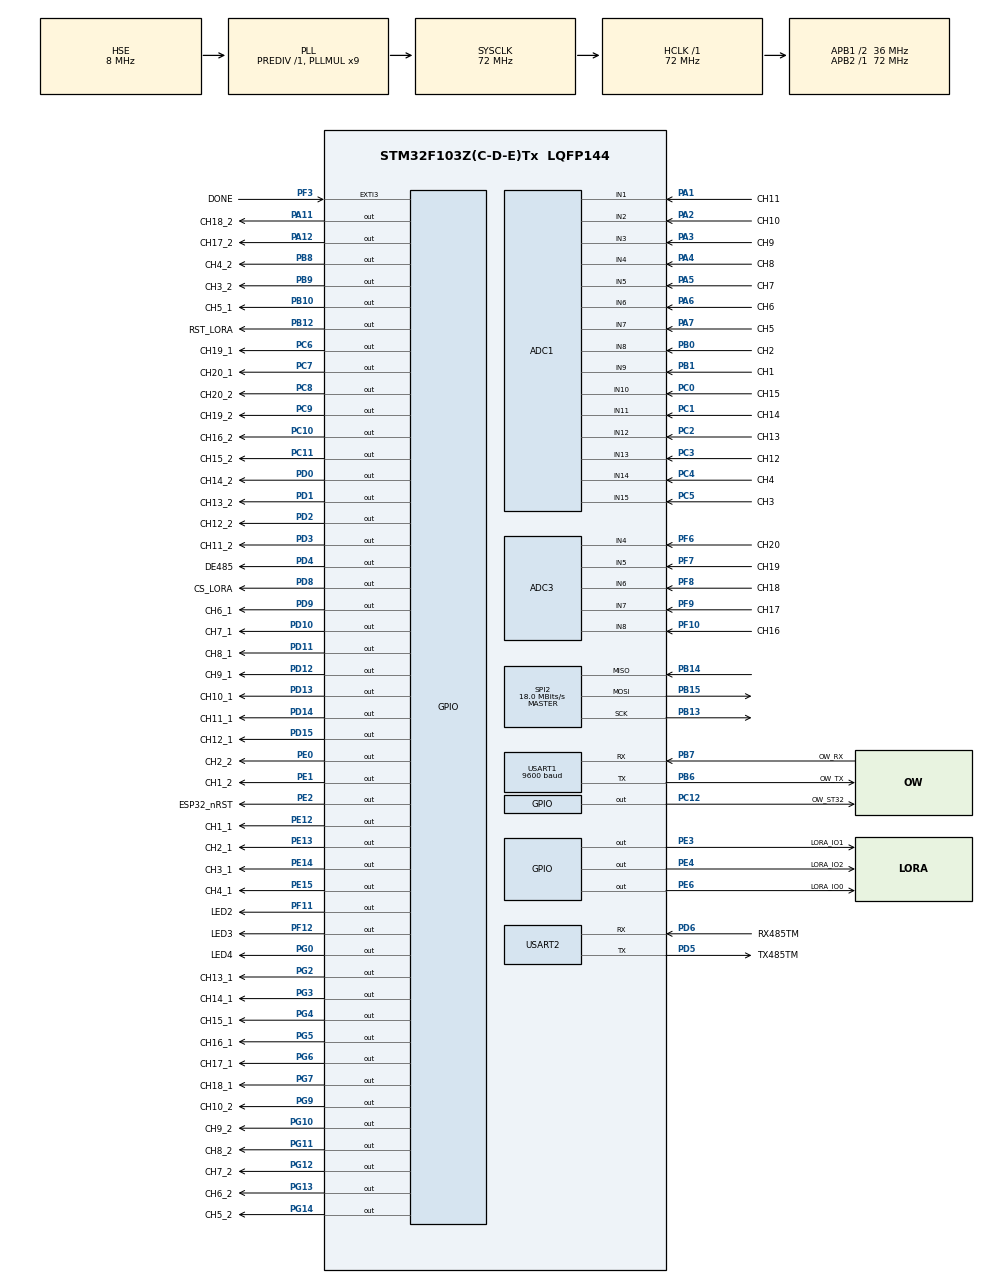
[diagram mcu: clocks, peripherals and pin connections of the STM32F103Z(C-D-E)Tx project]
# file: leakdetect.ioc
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ADC1.Channel-1\#ChannelRegularConversion=ADC_CHANNEL_9
ADC1.NbrOfConversionFlag=1
ADC1.Rank-1\#ChannelRegularConversion=1
ADC1.SamplingTime-1\#ChannelRegularConversion=ADC_SAMPLETIME_1CYCLE_5
ADC1.master=1
ADC3.Channel-1\#ChannelRegularConversion=ADC_CHANNEL_8
ADC3.NbrOfConversionFlag=1
ADC3.Rank-1\#ChannelRegularConversion=1
ADC3.SamplingTime-1\#ChannelRegularConversion=ADC_SAMPLETIME_1CYCLE_5
Dma.Request0=SPI2_RX
Dma.Request1=SPI2_TX
Dma.Request2=USART2_RX
Dma.Request3=USART2_TX
Dma.SPI2_RX.0.Direction=DMA_PERIPH_TO_MEMORY
Dma.SPI2_RX.0.Instance=DMA1_Channel4
Dma.SPI2_RX.0.MemDataAlignment=DMA_MDATAALIGN_BYTE
Dma.SPI2_RX.0.MemInc=DMA_MINC_ENABLE
Dma.SPI2_RX.0.Mode=DMA_NORMAL
Dma.SPI2_RX.0.PeriphDataAlignment=DMA_PDATAALIGN_BYTE
Dma.SPI2_RX.0.PeriphInc=DMA_PINC_DISABLE
Dma.SPI2_RX.0.Priority=DMA_PRIORITY_LOW
Dma.SPI2_TX.1.Direction=DMA_MEMORY_TO_PERIPH
Dma.SPI2_TX.1.Instance=DMA1_Channel5
Dma.SPI2_TX.1.MemDataAlignment=DMA_MDATAALIGN_BYTE
Dma.SPI2_TX.1.MemInc=DMA_MINC_ENABLE
Dma.SPI2_TX.1.Mode=DMA_NORMAL
Dma.SPI2_TX.1.PeriphDataAlignment=DMA_PDATAALIGN_BYTE
Dma.SPI2_TX.1.PeriphInc=DMA_PINC_DISABLE
Dma.SPI2_TX.1.Priority=DMA_PRIORITY_LOW
Dma.USART2_RX.2.Direction=DMA_PERIPH_TO_MEMORY
Dma.USART2_RX.2.Instance=DMA1_Channel6
Dma.USART2_RX.2.MemDataAlignment=DMA_MDATAALIGN_BYTE
Dma.USART2_RX.2.MemInc=DMA_MINC_ENABLE
Dma.USART2_RX.2.Mode=DMA_NORMAL
Dma.USART2_RX.2.PeriphDataAlignment=DMA_PDATAALIGN_BYTE
Dma.USART2_RX.2.PeriphInc=DMA_PINC_DISABLE
Dma.USART2_RX.2.Priority=DMA_PRIORITY_LOW
Dma.USART2_TX.3.Direction=DMA_MEMORY_TO_PERIPH
Dma.USART2_TX.3.Instance=DMA1_Channel7
Dma.USART2_TX.3.MemDataAlignment=DMA_MDATAALIGN_BYTE
Dma.USART2_TX.3.MemInc=DMA_MINC_ENABLE
Dma.USART2_TX.3.Mode=DMA_NORMAL
Dma.USART2_TX.3.PeriphDataAlignment=DMA_PDATAALIGN_BYTE
Dma.USART2_TX.3.PeriphInc=DMA_PINC_DISABLE
Dma.USART2_TX.3.Priority=DMA_PRIORITY_LOW
FREERTOS.Tasks01=defaultTask,0,128,StartDefaultTask,Default,NULL,Dynamic,NULL,NULL;modbusTask,0,128,StartTaskModBus,Default,NULL,Static,modbusTaskBuffer,modbusTaskControlBlock;leakMeterTask,0,128,StartTaskLeakMeter,Default,NULL,Static,leakMeterTaskBuffer,leakMeterTaskControlBlock;oneWireTask,-3,128,StartTaskOneWire,Default,NULL,Static,oneWireTaskBuffer,oneWireTaskControlBlock
FREERTOS.configCHECK_FOR_STACK_OVERFLOW=2
FREERTOS.configGENERATE_RUN_TIME_STATS=1
FREERTOS.configRECORD_STACK_HIGH_ADDRESS=1
FREERTOS.configUSE_MALLOC_FAILED_HOOK=1
FREERTOS.configUSE_NEWLIB_REENTRANT=1
FREERTOS.configUSE_STATS_FORMATTING_FUNCTIONS=1
FREERTOS.configUSE_TICKLESS_IDLE=1
Mcu.Family=STM32F1
Mcu.Name=STM32F103Z(C-D-E)Tx
Mcu.Package=LQFP144
NVIC.ADC1_2_IRQn=true\:5\:0\:false\:false\:true\:true\:true\:true\:true
NVIC.ADC3_IRQn=true\:5\:0\:false\:false\:true\:true\:true\:true\:true
NVIC.DMA1_Channel4_IRQn=true\:5\:0\:false\:false\:true\:true\:false\:true\:true
NVIC.DMA1_Channel5_IRQn=true\:5\:0\:false\:false\:true\:true\:false\:true\:true
NVIC.DMA1_Channel6_IRQn=true\:5\:0\:false\:false\:true\:true\:false\:true\:true
NVIC.DMA1_Channel7_IRQn=true\:5\:0\:false\:false\:true\:true\:false\:true\:true
NVIC.PriorityGroup=NVIC_PRIORITYGROUP_4
NVIC.RTC_IRQn=true\:5\:0\:false\:false\:true\:true\:true\:true\:true
NVIC.SPI2_IRQn=true\:5\:0\:false\:false\:true\:true\:true\:true\:true
NVIC.TIM8_UP_IRQn=true\:15\:0\:false\:false\:true\:false\:false\:true\:true
NVIC.TimeBase=TIM8_UP_IRQn
NVIC.TimeBaseIP=TIM8
NVIC.USART1_IRQn=true\:5\:0\:false\:false\:true\:true\:true\:true\:true
NVIC.USART2_IRQn=true\:5\:0\:false\:false\:true\:true\:true\:true\:true
OSC_IN.GPIO_Label=OSC_IN
OSC_IN.Mode=HSE-External-Oscillator
OSC_IN.Signal=RCC_OSC_IN
OSC_OUT.GPIO_Label=OSC_OUT
OSC_OUT.Mode=HSE-External-Oscillator
OSC_OUT.Signal=RCC_OSC_OUT
PA0-WKUP.Mode=SYS_WakeUp0
PA0-WKUP.Signal=SYS_WKUP
PA1.GPIO_Label=CH11
PA1.Signal=ADCx_IN1
PA11.GPIO_Label=CH18_2
PA11.Signal=GPIO_Output
PA12.GPIO_Label=CH17_2
PA12.Signal=GPIO_Output
PA13.GPIO_Label=JTMS_SWDIO
PA13.Mode=Serial_Wire
PA13.Signal=SYS_JTMS-SWDIO
PA14.GPIO_Label=JTCK_SWCLK
PA14.Mode=Serial_Wire
PA14.Signal=SYS_JTCK-SWCLK
PA15.GPIO_Label=JTDI
PA15.Signal=SYS_JTDI
PA2.GPIO_Label=CH10
PA2.Signal=ADCx_IN2
PA3.GPIO_Label=CH9
PA3.Signal=ADCx_IN3
PA4.GPIO_Label=CH8
PA4.Signal=ADCx_IN4
PA5.GPIO_Label=CH7
PA5.Signal=ADCx_IN5
PA6.GPIO_Label=CH6
PA6.Signal=ADCx_IN6
PA7.GPIO_Label=CH5
PA7.Signal=ADCx_IN7
PB0.GPIO_Label=CH2
PB0.Signal=ADCx_IN8
PB1.GPIO_Label=CH1
PB1.Signal=ADCx_IN9
PB10.GPIO_Label=CH5_1
PB10.Signal=GPIO_Output
PB12.GPIO_Label=RST_LORA
PB12.Signal=GPIO_Output
PB13.Mode=Full_Duplex_Master
PB13.Signal=SPI2_SCK
PB14.Mode=Full_Duplex_Master
PB14.Signal=SPI2_MISO
PB15.Mode=Full_Duplex_Master
PB15.Signal=SPI2_MOSI
PB4.GPIO_Label=JTRST
PB4.Signal=SYS_NJTRST
PB6.GPIO_Label=OW_TX
PB6.Mode=Asynchronous
PB6.Signal=USART1_TX
PB7.GPIO_Label=OW_RX
PB7.GPIO_PuPd=GPIO_PULLUP
PB7.Mode=Asynchronous
PB7.Signal=USART1_RX
PB8.GPIO_Label=CH4_2
PB8.Signal=GPIO_Output
PB9.GPIO_Label=CH3_2
PB9.Signal=GPIO_Output
PC0.GPIO_Label=CH15
PC0.Signal=ADCx_IN10
PC1.GPIO_Label=CH14
PC1.Signal=ADCx_IN11
PC10.GPIO_Label=CH16_2
PC10.Signal=GPIO_Output
PC11.GPIO_Label=CH15_2
PC11.Signal=GPIO_Output
PC12.GPIO_Label=OW_ST32
PC12.Signal=GPIO_Output
PC14-OSC32_IN.Mode=LSE-External-Oscillator
PC14-OSC32_IN.Signal=RCC_OSC32_IN
PC15-OSC32_OUT.Mode=LSE-External-Oscillator
PC15-OSC32_OUT.Signal=RCC_OSC32_OUT
PC2.GPIO_Label=CH13
PC2.Signal=ADCx_IN12
PC3.GPIO_Label=CH12
PC3.Signal=ADCx_IN13
PC4.GPIO_Label=CH4
PC4.Signal=ADCx_IN14
PC5.GPIO_Label=CH3
PC5.Signal=ADCx_IN15
PC6.GPIO_Label=CH19_1
PC6.Signal=GPIO_Output
PC7.GPIO_Label=CH20_1
PC7.Signal=GPIO_Output
PC8.GPIO_Label=CH20_2
PC8.Signal=GPIO_Output
PC9.GPIO_Label=CH19_2
PC9.Signal=GPIO_Output
PD0.GPIO_Label=CH14_2
PD0.Signal=GPIO_Output
PD1.GPIO_Label=CH13_2
PD1.Signal=GPIO_Output
PD10.GPIO_Label=CH7_1
PD10.Signal=GPIO_Output
PD11.GPIO_Label=CH8_1
PD11.Signal=GPIO_Output
PD12.GPIO_Label=CH9_1
PD12.Signal=GPIO_Output
PD13.GPIO_Label=CH10_1
PD13.Signal=GPIO_Output
PD14.GPIO_Label=CH11_1
PD14.Signal=GPIO_Output
PD15.GPIO_Label=CH12_1
PD15.Signal=GPIO_Output
PD2.GPIO_Label=CH12_2
PD2.Signal=GPIO_Output
PD3.GPIO_Label=CH11_2
PD3.Signal=GPIO_Output
PD4.GPIO_Label=DE485
PD4.Signal=GPIO_Output
PD5.GPIO_Label=TX485TM
PD5.Mode=Asynchronous
PD5.Signal=USART2_TX
PD6.GPIO_Label=RX485TM
PD6.GPIO_PuPd=GPIO_PULLUP
PD6.Mode=Asynchronous
PD6.Signal=USART2_RX
PD8.GPIO_Label=CS_LORA
PD8.Signal=GPIO_Output
PD9.GPIO_Label=CH6_1
PD9.Signal=GPIO_Output
PE0.GPIO_Label=CH2_2
PE0.Signal=GPIO_Output
PE1.GPIO_Label=CH1_2
PE1.Signal=GPIO_Output
PE12.GPIO_Label=CH1_1
PE12.Signal=GPIO_Output
PE13.GPIO_Label=CH2_1
PE13.Signal=GPIO_Output
PE14.GPIO_Label=CH3_1
PE14.Signal=GPIO_Output
PE15.GPIO_Label=CH4_1
PE15.Signal=GPIO_Output
PE2.GPIO_Label=ESP32_nRST
PE2.Signal=GPIO_Output
PE3.GPIO_Label=LORA_IO1
PE3.Signal=GPIO_Output
PE4.GPIO_Label=LORA_IO2
PE4.Signal=GPIO_Output
PE6.GPIO_Label=LORA_IO0
PE6.Signal=GPIO_Output
PF10.GPIO_Label=CH16
PF10.Mode=IN8
PF10.Signal=ADC3_IN8
PF11.GPIO_Label=LED2
PF11.Signal=GPIO_Output
PF12.GPIO_Label=LED3
PF12.Signal=GPIO_Output
PF3.GPIO_Label=DONE
PF3.Signal=GPXTI3
PF6.GPIO_Label=CH20
PF6.Mode=IN4
PF6.Signal=ADC3_IN4
PF7.GPIO_Label=CH19
PF7.Mode=IN5
PF7.Signal=ADC3_IN5
PF8.GPIO_Label=CH18
PF8.Mode=IN6
PF8.Signal=ADC3_IN6
PF9.GPIO_Label=CH17
PF9.Mode=IN7
PF9.Signal=ADC3_IN7
PG0.GPIO_Label=LED4
PG0.Signal=GPIO_Output
PG10.GPIO_Label=CH9_2
PG10.Signal=GPIO_Output
PG11.GPIO_Label=CH8_2
PG11.Signal=GPIO_Output
PG12.GPIO_Label=CH7_2
PG12.Signal=GPIO_Output
PG13.GPIO_Label=CH6_2
PG13.Signal=GPIO_Output
PG14.GPIO_Label=CH5_2
PG14.Signal=GPIO_Output
PG2.GPIO_Label=CH13_1
PG2.Signal=GPIO_Output
PG3.GPIO_Label=CH14_1
PG3.Signal=GPIO_Output
PG4.GPIO_Label=CH15_1
PG4.Signal=GPIO_Output
PG5.GPIO_Label=CH16_1
PG5.Signal=GPIO_Output
PG6.GPIO_Label=CH17_1
PG6.Signal=GPIO_Output
PG7.GPIO_Label=CH18_1
PG7.Signal=GPIO_Output
PG9.GPIO_Label=CH10_2
PG9.Signal=GPIO_Output
ProjectManager.HeapSize=0x200
ProjectManager.StackSize=0x400
ProjectManager.TargetToolchain=STM32CubeIDE
RCC.ADCPresc=RCC_ADCPCLK2_DIV6
RCC.AHBFreq_Value=72000000
RCC.APB1CLKDivider=RCC_HCLK_DIV2
RCC.APB1Freq_Value=36000000
RCC.APB1TimFreq_Value=72000000
RCC.APB2Freq_Value=72000000
RCC.APB2TimFreq_Value=72000000
RCC.HCLKFreq_Value=72000000
RCC.PLLMUL=RCC_PLL_MUL9
RCC.PLLSourceVirtual=RCC_PLLSOURCE_HSE
RCC.RTCClockSelection=RCC_RTCCLKSOURCE_LSE
RCC.SYSCLKFreq_VALUE=72000000
RCC.SYSCLKSource=RCC_SYSCLKSOURCE_PLLCLK
RCC.USBFreq_Value=72000000
SH.ADCx_IN1.0=ADC1_IN1,IN1
SH.ADCx_IN10.0=ADC1_IN10,IN10
SH.ADCx_IN11.0=ADC1_IN11,IN11
SH.ADCx_IN12.0=ADC1_IN12,IN12
SH.ADCx_IN13.0=ADC1_IN13,IN13
SH.ADCx_IN14.0=ADC1_IN14,IN14
SH.ADCx_IN15.0=ADC1_IN15,IN15
SH.ADCx_IN2.0=ADC1_IN2,IN2
SH.ADCx_IN3.0=ADC1_IN3,IN3
SH.ADCx_IN4.0=ADC1_IN4,IN4
SH.ADCx_IN5.0=ADC1_IN5,IN5
SH.ADCx_IN6.0=ADC1_IN6,IN6
SH.ADCx_IN7.0=ADC1_IN7,IN7
SH.ADCx_IN8.0=ADC1_IN8,IN8
SH.ADCx_IN9.0=ADC1_IN9,IN9
SPI2.BaudRatePrescaler=SPI_BAUDRATEPRESCALER_2
SPI2.CalculateBaudRate=18.0 MBits/s
SPI2.Direction=SPI_DIRECTION_2LINES
SPI2.Mode=SPI_MODE_MASTER
SPI2.VirtualType=VM_MASTER
USART1.BaudRate=9600
USART1.VirtualMode=VM_ASYNC
USART2.VirtualMode=VM_ASYNC
VP_CRC_VS_CRC.Mode=CRC_Activate
VP_FREERTOS_VS_CMSIS_V1.Mode=CMSIS_V1
VP_IWDG_VS_IWDG.Mode=IWDG_Activate
VP_RTC_VS_RTC_Activate.Mode=RTC_Enabled
VP_RTC_VS_RTC_Calendar.Mode=RTC_Calendar
VP_SYS_VS_tim8.Mode=TIM8
board=custom

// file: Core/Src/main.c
/* USER CODE BEGIN Header */
/**
  ******************************************************************************
  * @file           : main.c
  * @brief          : Main program body
  ******************************************************************************
  * @attention
  *
  * Copyright (c) 2024 STMicroelectronics.
  * All rights reserved.
  *
  * This software is licensed under terms that can be found in the LICENSE file
  * in the root directory of this software component.
  * If no LICENSE file comes with this software, it is provided AS-IS.
  *
  ******************************************************************************
  */
/* USER CODE END Header */
#include "main.h"
#include "cmsis_os.h"

/* USER CODE BEGIN Includes */
#include <stdio.h>
#include <string.h>
#include <math.h>
/* USER CODE END Includes */

/* USER CODE BEGIN PD */
#define VREF        3.3   // Опорное напряжение АЦП
#define ADC_MAX     4095   // Максимальное значение для 12-битного АЦП
#define R1          10000  // Значение известного сопротивления R1 в омах
#define UART_BUFFER_SIZE 256
/* USER CODE END PD */

ADC_HandleTypeDef hadc1;
ADC_HandleTypeDef hadc3;

CRC_HandleTypeDef hcrc;

IWDG_HandleTypeDef hiwdg;

RTC_HandleTypeDef hrtc;

SPI_HandleTypeDef hspi2;
DMA_HandleTypeDef hdma_spi2_rx;
DMA_HandleTypeDef hdma_spi2_tx;

UART_HandleTypeDef huart1;
UART_HandleTypeDef huart2;
DMA_HandleTypeDef hdma_usart2_rx;
DMA_HandleTypeDef hdma_usart2_tx;

osThreadId defaultTaskHandle;
osThreadId modbusTaskHandle;
uint32_t modbusTaskBuffer[ 128 ];
osStaticThreadDef_t modbusTaskControlBlock;
osThreadId leakMeterTaskHandle;
uint32_t leakMeterTaskBuffer[ 128 ];
osStaticThreadDef_t leakMeterTaskControlBlock;
osThreadId oneWireTaskHandle;
uint32_t oneWireTaskBuffer[ 128 ];
osStaticThreadDef_t oneWireTaskControlBlock;
/* USER CODE BEGIN PV */
typedef struct {
    GPIO_TypeDef* gpio_port1;  // Указатель на порт GPIO 1 канал
    uint16_t toggle_pin1;      // Первый пин для ToggleCurrentDirection
    GPIO_TypeDef* gpio_port2;  // Указатель на порт GPIO 2 канал
    uint16_t toggle_pin2;      // Второй пин для ToggleCurrentDirection
    uint32_t adc_channel;      // Канал АЦП, используемый для данной группы
    ADC_HandleTypeDef* hadc;   // Указатель на обработчик АЦП
    uint8_t channel_number;    // Номер канала
} ChannelConfig;

ChannelConfig channels[] = {

    {GPIOE, GPIO_PIN_12, GPIOE, GPIO_PIN_1, ADC_CHANNEL_9, &hadc1, 1}, // канал 1
    {GPIOE, GPIO_PIN_13, GPIOE, GPIO_PIN_0, ADC_CHANNEL_8, &hadc1, 2}, // канал 2
    {GPIOE, GPIO_PIN_14, GPIOB, GPIO_PIN_9, ADC_CHANNEL_15, &hadc1, 3}, // канал 3
    {GPIOE, GPIO_PIN_15, GPIOB, GPIO_PIN_8, ADC_CHANNEL_14, &hadc1, 4}, // канал 4
    {GPIOB, GPIO_PIN_10, GPIOG, GPIO_PIN_14, ADC_CHANNEL_7, &hadc1, 5}, // канал 5
    {GPIOD, GPIO_PIN_9, GPIOG, GPIO_PIN_13, ADC_CHANNEL_6, &hadc1, 6}, // канал 6
    {GPIOD, GPIO_PIN_10, GPIOG, GPIO_PIN_12, ADC_CHANNEL_5, &hadc1, 7}, // канал 7
    {GPIOD, GPIO_PIN_11, GPIOG, GPIO_PIN_11, ADC_CHANNEL_4, &hadc1, 8}, // канал 8
    {GPIOD, GPIO_PIN_12, GPIOG, GPIO_PIN_10, ADC_CHANNEL_3, &hadc1, 9}, // канал 9
    {GPIOD, GPIO_PIN_13, GPIOG, GPIO_PIN_9, ADC_CHANNEL_2, &hadc1, 10}, // канал 10
    {GPIOD, GPIO_PIN_14, GPIOD, GPIO_PIN_3, ADC_CHANNEL_1, &hadc1, 11}, // канал 11
    {GPIOD, GPIO_PIN_15, GPIOD, GPIO_PIN_2, ADC_CHANNEL_13, &hadc1, 12}, // канал 12
    {GPIOG, GPIO_PIN_2, GPIOD, GPIO_PIN_1, ADC_CHANNEL_12, &hadc1, 13}, // канал 13
    {GPIOG, GPIO_PIN_3, GPIOD, GPIO_PIN_0, ADC_CHANNEL_11, &hadc1, 14}, // канал 14
    {GPIOG, GPIO_PIN_4, GPIOC, GPIO_PIN_11, ADC_CHANNEL_10, &hadc1, 15}, // канал 15
    {GPIOG, GPIO_PIN_5, GPIOC, GPIO_PIN_10, ADC_CHANNEL_8, &hadc3, 16}, // канал 16
    {GPIOG, GPIO_PIN_6, GPIOA, GPIO_PIN_12, ADC_CHANNEL_7, &hadc3, 17}, // канал 17
    {GPIOG, GPIO_PIN_7, GPIOA, GPIO_PIN_11, ADC_CHANNEL_6, &hadc3, 18}, // канал 18
    {GPIOC, GPIO_PIN_6, GPIOC, GPIO_PIN_9, ADC_CHANNEL_5, &hadc3, 19}, // канал 19

    {GPIOC, GPIO_PIN_7, GPIOC, GPIO_PIN_8, ADC_CHANNEL_4, &hadc3, 20}, // канал 20
};

void ToggleCurrentDirection(GPIO_TypeDef* gpio_port1, uint16_t pin1, GPIO_TypeDef* gpio_port2, uint16_t pin2, uint16_t time_delay);
void ProcessChannel(ChannelConfig* channel);
void ConfigureUnusedChannels(ChannelConfig* active_channel);
void ResetChannelConfigs(void);
/* USER CODE END PV */

void SystemClock_Config(void);
static void MX_GPIO_Init(void);
static void MX_DMA_Init(void);
static void MX_ADC1_Init(void);
static void MX_ADC3_Init(void);
static void MX_USART1_UART_Init(void);
static void MX_RTC_Init(void);
static void MX_SPI2_Init(void);
static void MX_USART2_UART_Init(void);
static void MX_CRC_Init(void);
static void MX_IWDG_Init(void);
void StartDefaultTask(void const * argument);
void StartTaskModBus(void const * argument);
void StartTaskLeakMeter(void const * argument);
void StartTaskOneWire(void const * argument);

/* USER CODE BEGIN 0 */
int _write(int file, char *data, int len)
{
    // Отключите отладочный вывод через UART, чтобы избежать отправки лишних данных
    return len;
}
/* USER CODE END 0 */

int main(void)
{

  /* MCU Configuration--------------------------------------------------------*/

  /* Reset of all peripherals, Initializes the Flash interface and the Systick. */
  HAL_Init();

  /* Configure the system clock */
  SystemClock_Config();

  /* Initialize all configured peripherals */
  MX_GPIO_Init();
  MX_DMA_Init();
  MX_ADC1_Init();
  MX_ADC3_Init();
  MX_USART1_UART_Init();
  MX_RTC_Init();
  MX_SPI2_Init();
  MX_USART2_UART_Init();
  MX_CRC_Init();
  MX_IWDG_Init();

  /* Create the thread(s) */
  /* definition and creation of defaultTask */
  osThreadDef(defaultTask, StartDefaultTask, osPriorityNormal, 0, 128);
  defaultTaskHandle = osThreadCreate(osThread(defaultTask), NULL);

  /* definition and creation of modbusTask */
  osThreadStaticDef(modbusTask, StartTaskModBus, osPriorityNormal, 0, 128, modbusTaskBuffer, &modbusTaskControlBlock);
  modbusTaskHandle = osThreadCreate(osThread(modbusTask), NULL);

  /* definition and creation of leakMeterTask */
  osThreadStaticDef(leakMeterTask, StartTaskLeakMeter, osPriorityNormal, 0, 128, leakMeterTaskBuffer, &leakMeterTaskControlBlock);
  leakMeterTaskHandle = osThreadCreate(osThread(leakMeterTask), NULL);

  /* definition and creation of oneWireTask */
  osThreadStaticDef(oneWireTask, StartTaskOneWire, osPriorityIdle, 0, 128, oneWireTaskBuffer, &oneWireTaskControlBlock);
  oneWireTaskHandle = osThreadCreate(osThread(oneWireTask), NULL);

  /* Start scheduler */
  osKernelStart();

  /* We should never get here as control is now taken by the scheduler */

  /* Infinite loop */
  /* USER CODE BEGIN WHILE */
  while (1)
  {
    for (int i = 0; i < sizeof(channels)/sizeof(channels[0]); i++) {
         ProcessChannel(&channels[i]);
    }

    /* USER CODE END WHILE */

  }
}

void SystemClock_Config(void)
{
  RCC_OscInitTypeDef RCC_OscInitStruct = {0};
  RCC_ClkInitTypeDef RCC_ClkInitStruct = {0};
  RCC_PeriphCLKInitTypeDef PeriphClkInit = {0};

  /** Initializes the RCC Oscillators according to the specified parameters
  * in the RCC_OscInitTypeDef structure.
  */
  RCC_OscInitStruct.OscillatorType = RCC_OSCILLATORTYPE_LSI|RCC_OSCILLATORTYPE_HSE
                              |RCC_OSCILLATORTYPE_LSE;
  RCC_OscInitStruct.HSEState = RCC_HSE_ON;
  RCC_OscInitStruct.HSEPredivValue = RCC_HSE_PREDIV_DIV1;
  RCC_OscInitStruct.LSEState = RCC_LSE_ON;
  RCC_OscInitStruct.HSIState = RCC_HSI_ON;
  RCC_OscInitStruct.LSIState = RCC_LSI_ON;
  RCC_OscInitStruct.PLL.PLLState = RCC_PLL_ON;
  RCC_OscInitStruct.PLL.PLLSource = RCC_PLLSOURCE_HSE;
  RCC_OscInitStruct.PLL.PLLMUL = RCC_PLL_MUL9;
  if (HAL_RCC_OscConfig(&RCC_OscInitStruct) != HAL_OK)
  {
    Error_Handler();
  }

  /** Initializes the CPU, AHB and APB buses clocks
  */
  RCC_ClkInitStruct.ClockType = RCC_CLOCKTYPE_HCLK|RCC_CLOCKTYPE_SYSCLK
                              |RCC_CLOCKTYPE_PCLK1|RCC_CLOCKTYPE_PCLK2;
  RCC_ClkInitStruct.SYSCLKSource = RCC_SYSCLKSOURCE_PLLCLK;
  RCC_ClkInitStruct.AHBCLKDivider = RCC_SYSCLK_DIV1;
  RCC_ClkInitStruct.APB1CLKDivider = RCC_HCLK_DIV2;
  RCC_ClkInitStruct.APB2CLKDivider = RCC_HCLK_DIV1;

  if (HAL_RCC_ClockConfig(&RCC_ClkInitStruct, FLASH_LATENCY_2) != HAL_OK)
  {
    Error_Handler();
  }
  PeriphClkInit.PeriphClockSelection = RCC_PERIPHCLK_RTC|RCC_PERIPHCLK_ADC;
  PeriphClkInit.RTCClockSelection = RCC_RTCCLKSOURCE_LSE;
  PeriphClkInit.AdcClockSelection = RCC_ADCPCLK2_DIV6;
  if (HAL_RCCEx_PeriphCLKConfig(&PeriphClkInit) != HAL_OK)
  {
    Error_Handler();
  }
}

static void MX_ADC1_Init(void)
{

  ADC_ChannelConfTypeDef sConfig = {0};

  /** Common config
  */
  hadc1.Instance = ADC1;
  hadc1.Init.ScanConvMode = ADC_SCAN_DISABLE;
  hadc1.Init.ContinuousConvMode = DISABLE;
  hadc1.Init.DiscontinuousConvMode = DISABLE;
  hadc1.Init.ExternalTrigConv = ADC_SOFTWARE_START;
  hadc1.Init.DataAlign = ADC_DATAALIGN_RIGHT;
  hadc1.Init.NbrOfConversion = 1;
  if (HAL_ADC_Init(&hadc1) != HAL_OK)
  {
    Error_Handler();
  }

  /** Configure Regular Channel
  */
  sConfig.Channel = ADC_CHANNEL_9;
  sConfig.Rank = ADC_REGULAR_RANK_1;
  sConfig.SamplingTime = ADC_SAMPLETIME_1CYCLE_5;
  if (HAL_ADC_ConfigChannel(&hadc1, &sConfig) != HAL_OK)
  {
    Error_Handler();
  }

}

static void MX_ADC3_Init(void)
{

  ADC_ChannelConfTypeDef sConfig = {0};

  /** Common config
  */
  hadc3.Instance = ADC3;
  hadc3.Init.ScanConvMode = ADC_SCAN_DISABLE;
  hadc3.Init.ContinuousConvMode = DISABLE;
  hadc3.Init.DiscontinuousConvMode = DISABLE;
  hadc3.Init.ExternalTrigConv = ADC_SOFTWARE_START;
  hadc3.Init.DataAlign = ADC_DATAALIGN_RIGHT;
  hadc3.Init.NbrOfConversion = 1;
  if (HAL_ADC_Init(&hadc3) != HAL_OK)
  {
    Error_Handler();
  }

  /** Configure Regular Channel
  */
  sConfig.Channel = ADC_CHANNEL_8;
  sConfig.Rank = ADC_REGULAR_RANK_1;
  sConfig.SamplingTime = ADC_SAMPLETIME_1CYCLE_5;
  if (HAL_ADC_ConfigChannel(&hadc3, &sConfig) != HAL_OK)
  {
    Error_Handler();
  }

}

static void MX_CRC_Init(void)
{

  hcrc.Instance = CRC;
  if (HAL_CRC_Init(&hcrc) != HAL_OK)
  {
    Error_Handler();
  }

}

static void MX_IWDG_Init(void)
{

  hiwdg.Instance = IWDG;
  hiwdg.Init.Prescaler = IWDG_PRESCALER_4;
  hiwdg.Init.Reload = 4095;
  if (HAL_IWDG_Init(&hiwdg) != HAL_OK)
  {
    Error_Handler();
  }

}

static void MX_RTC_Init(void)
{

  RTC_TimeTypeDef sTime = {0};
  RTC_DateTypeDef DateToUpdate = {0};

  /** Initialize RTC Only
  */
  hrtc.Instance = RTC;
  hrtc.Init.AsynchPrediv = RTC_AUTO_1_SECOND;
  hrtc.Init.OutPut = RTC_OUTPUTSOURCE_ALARM;
  if (HAL_RTC_Init(&hrtc) != HAL_OK)
  {
    Error_Handler();
  }

  /** Initialize RTC and set the Time and Date
  */
  sTime.Hours = 0x0;
  sTime.Minutes = 0x0;
  sTime.Seconds = 0x0;

  if (HAL_RTC_SetTime(&hrtc, &sTime, RTC_FORMAT_BCD) != HAL_OK)
  {
    Error_Handler();
  }
  DateToUpdate.WeekDay = RTC_WEEKDAY_MONDAY;
  DateToUpdate.Month = RTC_MONTH_JANUARY;
  DateToUpdate.Date = 0x1;
  DateToUpdate.Year = 0x0;

  if (HAL_RTC_SetDate(&hrtc, &DateToUpdate, RTC_FORMAT_BCD) != HAL_OK)
  {
    Error_Handler();
  }

}

static void MX_SPI2_Init(void)
{

  /* SPI2 parameter configuration*/
  hspi2.Instance = SPI2;
  hspi2.Init.Mode = SPI_MODE_MASTER;
  hspi2.Init.Direction = SPI_DIRECTION_2LINES;
  hspi2.Init.DataSize = SPI_DATASIZE_8BIT;
  hspi2.Init.CLKPolarity = SPI_POLARITY_LOW;
  hspi2.Init.CLKPhase = SPI_PHASE_1EDGE;
  hspi2.Init.NSS = SPI_NSS_SOFT;
  hspi2.Init.BaudRatePrescaler = SPI_BAUDRATEPRESCALER_2;
  hspi2.Init.FirstBit = SPI_FIRSTBIT_MSB;
  hspi2.Init.TIMode = SPI_TIMODE_DISABLE;
  hspi2.Init.CRCCalculation = SPI_CRCCALCULATION_DISABLE;
  hspi2.Init.CRCPolynomial = 10;
  if (HAL_SPI_Init(&hspi2) != HAL_OK)
  {
    Error_Handler();
  }

}

static void MX_USART1_UART_Init(void)
{

  huart1.Instance = USART1;
  huart1.Init.BaudRate = 9600;
  huart1.Init.WordLength = UART_WORDLENGTH_8B;
  huart1.Init.StopBits = UART_STOPBITS_1;
  huart1.Init.Parity = UART_PARITY_NONE;
  huart1.Init.Mode = UART_MODE_TX_RX;
  huart1.Init.HwFlowCtl = UART_HWCONTROL_NONE;
  huart1.Init.OverSampling = UART_OVERSAMPLING_16;
  if (HAL_UART_Init(&huart1) != HAL_OK)
  {
    Error_Handler();
  }

}

static void MX_USART2_UART_Init(void)
{

  huart2.Instance = USART2;
  huart2.Init.BaudRate = 115200;
  huart2.Init.WordLength = UART_WORDLENGTH_8B;
  huart2.Init.StopBits = UART_STOPBITS_1;
  huart2.Init.Parity = UART_PARITY_NONE;
  huart2.Init.Mode = UART_MODE_TX_RX;
  huart2.Init.HwFlowCtl = UART_HWCONTROL_NONE;
  huart2.Init.OverSampling = UART_OVERSAMPLING_16;
  if (HAL_UART_Init(&huart2) != HAL_OK)
  {
    Error_Handler();
  }

}

static void MX_DMA_Init(void)
{

  /* DMA controller clock enable */
  __HAL_RCC_DMA1_CLK_ENABLE();

  /* DMA interrupt init */
  /* DMA1_Channel4_IRQn interrupt configuration */
  HAL_NVIC_SetPriority(DMA1_Channel4_IRQn, 5, 0);
  HAL_NVIC_EnableIRQ(DMA1_Channel4_IRQn);
  /* DMA1_Channel5_IRQn interrupt configuration */
  HAL_NVIC_SetPriority(DMA1_Channel5_IRQn, 5, 0);
  HAL_NVIC_EnableIRQ(DMA1_Channel5_IRQn);
  /* DMA1_Channel6_IRQn interrupt configuration */
  HAL_NVIC_SetPriority(DMA1_Channel6_IRQn, 5, 0);
  HAL_NVIC_EnableIRQ(DMA1_Channel6_IRQn);
  /* DMA1_Channel7_IRQn interrupt configuration */
  HAL_NVIC_SetPriority(DMA1_Channel7_IRQn, 5, 0);
  HAL_NVIC_EnableIRQ(DMA1_Channel7_IRQn);

}

static void MX_GPIO_Init(void)
{
  GPIO_InitTypeDef GPIO_InitStruct = {0};

  /* GPIO Ports Clock Enable */
  __HAL_RCC_GPIOE_CLK_ENABLE();
  __HAL_RCC_GPIOC_CLK_ENABLE();
  __HAL_RCC_GPIOF_CLK_ENABLE();
  __HAL_RCC_GPIOA_CLK_ENABLE();
  __HAL_RCC_GPIOB_CLK_ENABLE();
  __HAL_RCC_GPIOG_CLK_ENABLE();
  __HAL_RCC_GPIOD_CLK_ENABLE();

  /*Configure GPIO pin Output Level */
  HAL_GPIO_WritePin(GPIOE, ESP32_nRST_Pin|LORA_IO1_Pin|LORA_IO2_Pin|LORA_IO0_Pin
                          |CH1_1_Pin|CH2_1_Pin|CH3_1_Pin|CH4_1_Pin
                          |CH2_2_Pin|CH1_2_Pin, GPIO_PIN_RESET);

  /*Configure GPIO pin Output Level */
  HAL_GPIO_WritePin(GPIOF, LED2_Pin|LED3_Pin, GPIO_PIN_RESET);

  /*Configure GPIO pin Output Level */
  HAL_GPIO_WritePin(GPIOG, LED4_Pin|CH13_1_Pin|CH14_1_Pin|CH15_1_Pin
                          |CH16_1_Pin|CH17_1_Pin|CH18_1_Pin|CH10_2_Pin
                          |CH9_2_Pin|CH8_2_Pin|CH7_2_Pin|CH6_2_Pin
                          |CH5_2_Pin, GPIO_PIN_RESET);

  /*Configure GPIO pin Output Level */
  HAL_GPIO_WritePin(GPIOB, CH5_1_Pin|RST_LORA_Pin|CH4_2_Pin|CH3_2_Pin, GPIO_PIN_RESET);

  /*Configure GPIO pin Output Level */
  HAL_GPIO_WritePin(GPIOD, CS_LORA_Pin|CH6_1_Pin|CH7_1_Pin|CH8_1_Pin
                          |CH9_1_Pin|CH10_1_Pin|CH11_1_Pin|CH12_1_Pin
                          |CH14_2_Pin|CH13_2_Pin|CH12_2_Pin|CH11_2_Pin
                          |DE485_Pin, GPIO_PIN_RESET);

  /*Configure GPIO pin Output Level */
  HAL_GPIO_WritePin(GPIOC, CH19_1_Pin|CH20_1_Pin|CH20_2_Pin|CH19_2_Pin
                          |CH16_2_Pin|CH15_2_Pin|OW_ST32_Pin, GPIO_PIN_RESET);

  /*Configure GPIO pin Output Level */
  HAL_GPIO_WritePin(GPIOA, CH18_2_Pin|CH17_2_Pin, GPIO_PIN_RESET);

  /*Configure GPIO pins : ESP32_nRST_Pin LORA_IO1_Pin LORA_IO2_Pin LORA_IO0_Pin
                           CH1_1_Pin CH2_1_Pin CH3_1_Pin CH4_1_Pin
                           CH2_2_Pin CH1_2_Pin */
  GPIO_InitStruct.Pin = ESP32_nRST_Pin|LORA_IO1_Pin|LORA_IO2_Pin|LORA_IO0_Pin
                          |CH1_1_Pin|CH2_1_Pin|CH3_1_Pin|CH4_1_Pin
                          |CH2_2_Pin|CH1_2_Pin;
  GPIO_InitStruct.Mode = GPIO_MODE_OUTPUT_PP;
  GPIO_InitStruct.Pull = GPIO_NOPULL;
  GPIO_InitStruct.Speed = GPIO_SPEED_FREQ_LOW;
  HAL_GPIO_Init(GPIOE, &GPIO_InitStruct);

  /*Configure GPIO pin : DONE_Pin */
  GPIO_InitStruct.Pin = DONE_Pin;
  GPIO_InitStruct.Mode = GPIO_MODE_IT_RISING;
  GPIO_InitStruct.Pull = GPIO_NOPULL;
  HAL_GPIO_Init(DONE_GPIO_Port, &GPIO_InitStruct);

  /*Configure GPIO pins : LED2_Pin LED3_Pin */
  GPIO_InitStruct.Pin = LED2_Pin|LED3_Pin;
  GPIO_InitStruct.Mode = GPIO_MODE_OUTPUT_PP;
  GPIO_InitStruct.Pull = GPIO_NOPULL;
  GPIO_InitStruct.Speed = GPIO_SPEED_FREQ_LOW;
  HAL_GPIO_Init(GPIOF, &GPIO_InitStruct);

  /*Configure GPIO pins : LED4_Pin CH13_1_Pin CH14_1_Pin CH15_1_Pin
                           CH16_1_Pin CH17_1_Pin CH18_1_Pin CH10_2_Pin
                           CH9_2_Pin CH8_2_Pin CH7_2_Pin CH6_2_Pin
                           CH5_2_Pin */
  GPIO_InitStruct.Pin = LED4_Pin|CH13_1_Pin|CH14_1_Pin|CH15_1_Pin
                          |CH16_1_Pin|CH17_1_Pin|CH18_1_Pin|CH10_2_Pin
                          |CH9_2_Pin|CH8_2_Pin|CH7_2_Pin|CH6_2_Pin
                          |CH5_2_Pin;
  GPIO_InitStruct.Mode = GPIO_MODE_OUTPUT_PP;
  GPIO_InitStruct.Pull = GPIO_NOPULL;
  GPIO_InitStruct.Speed = GPIO_SPEED_FREQ_LOW;
  HAL_GPIO_Init(GPIOG, &GPIO_InitStruct);

  /*Configure GPIO pins : CH5_1_Pin RST_LORA_Pin CH4_2_Pin CH3_2_Pin */
  GPIO_InitStruct.Pin = CH5_1_Pin|RST_LORA_Pin|CH4_2_Pin|CH3_2_Pin;
  GPIO_InitStruct.Mode = GPIO_MODE_OUTPUT_PP;
  GPIO_InitStruct.Pull = GPIO_NOPULL;
  GPIO_InitStruct.Speed = GPIO_SPEED_FREQ_LOW;
  HAL_GPIO_Init(GPIOB, &GPIO_InitStruct);

  /*Configure GPIO pins : CS_LORA_Pin CH6_1_Pin CH7_1_Pin CH8_1_Pin
                           CH9_1_Pin CH10_1_Pin CH11_1_Pin CH12_1_Pin
                           CH14_2_Pin CH13_2_Pin CH12_2_Pin CH11_2_Pin
                           DE485_Pin */
  GPIO_InitStruct.Pin = CS_LORA_Pin|CH6_1_Pin|CH7_1_Pin|CH8_1_Pin
                          |CH9_1_Pin|CH10_1_Pin|CH11_1_Pin|CH12_1_Pin
                          |CH14_2_Pin|CH13_2_Pin|CH12_2_Pin|CH11_2_Pin
                          |DE485_Pin;
  GPIO_InitStruct.Mode = GPIO_MODE_OUTPUT_PP;
  GPIO_InitStruct.Pull = GPIO_NOPULL;
  GPIO_InitStruct.Speed = GPIO_SPEED_FREQ_LOW;
  HAL_GPIO_Init(GPIOD, &GPIO_InitStruct);

  /*Configure GPIO pins : CH19_1_Pin CH20_1_Pin CH20_2_Pin CH19_2_Pin
                           CH16_2_Pin CH15_2_Pin OW_ST32_Pin */
  GPIO_InitStruct.Pin = CH19_1_Pin|CH20_1_Pin|CH20_2_Pin|CH19_2_Pin
                          |CH16_2_Pin|CH15_2_Pin|OW_ST32_Pin;
  GPIO_InitStruct.Mode = GPIO_MODE_OUTPUT_PP;
  GPIO_InitStruct.Pull = GPIO_NOPULL;
  GPIO_InitStruct.Speed = GPIO_SPEED_FREQ_LOW;
  HAL_GPIO_Init(GPIOC, &GPIO_InitStruct);

  /*Configure GPIO pins : CH18_2_Pin CH17_2_Pin */
  GPIO_InitStruct.Pin = CH18_2_Pin|CH17_2_Pin;
  GPIO_InitStruct.Mode = GPIO_MODE_OUTPUT_PP;
  GPIO_InitStruct.Pull = GPIO_NOPULL;
  GPIO_InitStruct.Speed = GPIO_SPEED_FREQ_LOW;
  HAL_GPIO_Init(GPIOA, &GPIO_InitStruct);

}

/* USER CODE BEGIN 4 */
void SetUnusedChannelsHigh(ChannelConfig* active_channel) {
    // Перебираем все каналы и подаем высокий логический уровень на неактивные
    for (int i = 0; i < sizeof(channels)/sizeof(channels[0]); i++) {
        if (&channels[i] != active_channel) {
            HAL_GPIO_WritePin(channels[i].gpio_port1, channels[i].toggle_pin1, GPIO_PIN_SET);
            HAL_GPIO_WritePin(channels[i].gpio_port2, channels[i].toggle_pin2, GPIO_PIN_SET);
        }
    }
}

void ResetUnusedChannels(ChannelConfig* active_channel) {
    // Переводим все каналы обратно в низкий логический уровень
    for (int i = 0; i < sizeof(channels)/sizeof(channels[0]); i++) {
        if (&channels[i] != active_channel) {
            HAL_GPIO_WritePin(channels[i].gpio_port1, channels[i].toggle_pin1, GPIO_PIN_RESET);
            HAL_GPIO_WritePin(channels[i].gpio_port2, channels[i].toggle_pin2, GPIO_PIN_RESET);
        }
    }
}

void ProcessChannel(ChannelConfig* channel) {
    const int num_measurements = 12;
    uint16_t adc_values[num_measurements];
    float sum = 0;
    uint16_t max_value = 0;
    uint16_t min_value = 0xFFFF; // �?нициализируем минимальное значение максимальным возможным
    char msg[UART_BUFFER_SIZE];

    ADC_ChannelConfTypeDef sConfig = {0};

    // Устанавливаем высокий логический уровень на неиспользуемые каналы
    SetUnusedChannelsHigh(channel);

    // Настройка канала
    sConfig.Channel = channel->adc_channel;
    sConfig.Rank = ADC_REGULAR_RANK_1;
    sConfig.SamplingTime = ADC_SAMPLETIME_1CYCLE_5;
    if (HAL_ADC_ConfigChannel(channel->hadc, &sConfig) != HAL_OK) {
        Error_Handler();
    }

    for (int i = 0; i < num_measurements; i++) {
        ToggleCurrentDirection(channel->gpio_port1, channel->toggle_pin1, channel->gpio_port2, channel->toggle_pin2, 30);
        HAL_GPIO_WritePin(channel->gpio_port2, channel->toggle_pin2, GPIO_PIN_SET); // подача высокого уровня перед АЦП
        HAL_GPIO_WritePin(GPIOG, GPIO_PIN_0, GPIO_PIN_SET); //led on
        HAL_Delay(10);

        // Считывание значения АЦП
        HAL_ADC_Start(channel->hadc);
        HAL_ADC_PollForConversion(channel->hadc, HAL_MAX_DELAY);
        adc_values[i] = HAL_ADC_GetValue(channel->hadc);
        HAL_ADC_Stop(channel->hadc);

        sum += adc_values[i];
        if (adc_values[i] > max_value) {
            max_value = adc_values[i];
        }
        if (adc_values[i] < min_value) {
            min_value = adc_values[i];
        }

        HAL_GPIO_WritePin(channel->gpio_port2, channel->toggle_pin2, GPIO_PIN_RESET); // подача низкого уровня перед АЦП
        HAL_GPIO_WritePin(GPIOG, GPIO_PIN_0, GPIO_PIN_RESET); //led off
        HAL_Delay(10);
    }

    uint16_t average = (uint16_t)round(sum / num_measurements);

    // Отправляем только JSON-данные через UART
    sprintf(msg, "{\"channel\": %d, \"average\": %u, \"max\": %u, \"min\": %u}\r\n", channel->channel_number, average, max_value, min_value);
    HAL_UART_Transmit(&huart1, (uint8_t *)msg, strlen(msg), HAL_MAX_DELAY);
    printf("Sent JSON: %s\n", msg);

    // Сброс логического уровня на неиспользуемых каналах после измерения
    ResetUnusedChannels(channel);
}

void ToggleCurrentDirection(GPIO_TypeDef* gpio_port1, uint16_t pin1, GPIO_TypeDef* gpio_port2, uint16_t pin2, uint16_t time_delay) {
    for (int i = 0; i < 5; i++) {
        HAL_GPIO_WritePin(gpio_port1, pin1, GPIO_PIN_SET);
        HAL_GPIO_WritePin(GPIOF, GPIO_PIN_12, GPIO_PIN_SET);

        HAL_GPIO_WritePin(gpio_port2, pin2, GPIO_PIN_RESET);
        HAL_GPIO_WritePin(GPIOF, GPIO_PIN_11, GPIO_PIN_RESET);

        HAL_Delay(time_delay);
        HAL_GPIO_WritePin(gpio_port1, pin1, GPIO_PIN_RESET);
        HAL_GPIO_WritePin(GPIOF, GPIO_PIN_12, GPIO_PIN_RESET);

        HAL_GPIO_WritePin(gpio_port2, pin2, GPIO_PIN_SET);
        HAL_GPIO_WritePin(GPIOF, GPIO_PIN_11, GPIO_PIN_SET);

        HAL_Delay(time_delay);
    }
    HAL_GPIO_WritePin(gpio_port1, pin1, GPIO_PIN_RESET);
    HAL_GPIO_WritePin(GPIOF, GPIO_PIN_11, GPIO_PIN_RESET);

    HAL_GPIO_WritePin(gpio_port2, pin2, GPIO_PIN_RESET);
    HAL_GPIO_WritePin(GPIOF, GPIO_PIN_12, GPIO_PIN_RESET);

    HAL_Delay(time_delay);
}

float calculateResistance(uint16_t adc_value) {
    float v_out = (double)adc_value / ADC_MAX * VREF;
    if (v_out == 0) {
        return 0;  // �?збегаем деления на ноль
    }
    float resistance = (R1 * ((VREF / v_out) - 1)) / 10000;
    return resistance;
}

/* USER CODE END 4 */

void StartDefaultTask(void const * argument)
{
  for(;;)
  {
    osDelay(1);
  }
}

void StartTaskModBus(void const * argument)
{
  for(;;)
  {
    osDelay(1);
  }
}

void StartTaskLeakMeter(void const * argument)
{
  for(;;)
  {
    osDelay(1);
  }
}

void StartTaskOneWire(void const * argument)
{
  for(;;)
  {
    osDelay(1);
  }
}

void HAL_TIM_PeriodElapsedCallback(TIM_HandleTypeDef *htim)
{
  if (htim->Instance == TIM8) {
    HAL_IncTick();
  }
}

void Error_Handler(void)
{
  __disable_irq();
  while (1)
  {
  }
}

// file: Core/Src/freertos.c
/* USER CODE BEGIN Header */
/**
  ******************************************************************************
  * File Name          : freertos.c
  * Description        : Code for freertos applications
  ******************************************************************************
  * @attention
  *
  * Copyright (c) 2024 STMicroelectronics.
  * All rights reserved.
  *
  * This software is licensed under terms that can be found in the LICENSE file
  * in the root directory of this software component.
  * If no LICENSE file comes with this software, it is provided AS-IS.
  *
  ******************************************************************************
  */
/* USER CODE END Header */

#include "FreeRTOS.h"
#include "task.h"
#include "main.h"

/* GetIdleTaskMemory prototype (linked to static allocation support) */
void vApplicationGetIdleTaskMemory( StaticTask_t **ppxIdleTaskTCBBuffer, StackType_t **ppxIdleTaskStackBuffer, uint32_t *pulIdleTaskStackSize );

/* Hook prototypes */
void configureTimerForRunTimeStats(void);
unsigned long getRunTimeCounterValue(void);
void vApplicationStackOverflowHook(xTaskHandle xTask, signed char *pcTaskName);
void vApplicationMallocFailedHook(void);

/* USER CODE BEGIN 1 */
/* Functions needed when configGENERATE_RUN_TIME_STATS is on */
__weak void configureTimerForRunTimeStats(void)
{

}

__weak unsigned long getRunTimeCounterValue(void)
{
return 0;
}
/* USER CODE END 1 */

/* USER CODE BEGIN 4 */
void vApplicationStackOverflowHook(xTaskHandle xTask, signed char *pcTaskName)
{
   /* Run time stack overflow checking is performed if
   configCHECK_FOR_STACK_OVERFLOW is defined to 1 or 2. This hook function is
   called if a stack overflow is detected. */
}
/* USER CODE END 4 */

/* USER CODE BEGIN 5 */
void vApplicationMallocFailedHook(void)
{
   /* vApplicationMallocFailedHook() will only be called if
   configUSE_MALLOC_FAILED_HOOK is set to 1 in FreeRTOSConfig.h. It is a hook
   function that will get called if a call to pvPortMalloc() fails.
   pvPortMalloc() is called internally by the kernel whenever a task, queue,
   timer or semaphore is created. It is also called by various parts of the
   demo application. If heap_1.c or heap_2.c are used, then the size of the
   heap available to pvPortMalloc() is defined by configTOTAL_HEAP_SIZE in
   FreeRTOSConfig.h, and the xPortGetFreeHeapSize() API function can be used
   to query the size of free heap space that remains (although it does not
   provide information on how the remaining heap might be fragmented). */
}
/* USER CODE END 5 */

/* USER CODE BEGIN PREPOSTSLEEP */
__weak void PreSleepProcessing(uint32_t *ulExpectedIdleTime)
{
/* place for user code */
}

__weak void PostSleepProcessing(uint32_t *ulExpectedIdleTime)
{
/* place for user code */
}
/* USER CODE END PREPOSTSLEEP */

/* USER CODE BEGIN GET_IDLE_TASK_MEMORY */
static StaticTask_t xIdleTaskTCBBuffer;
static StackType_t xIdleStack[configMINIMAL_STACK_SIZE];

void vApplicationGetIdleTaskMemory( StaticTask_t **ppxIdleTaskTCBBuffer, StackType_t **ppxIdleTaskStackBuffer, uint32_t *pulIdleTaskStackSize )
{
  *ppxIdleTaskTCBBuffer = &xIdleTaskTCBBuffer;
  *ppxIdleTaskStackBuffer = &xIdleStack[0];
  *pulIdleTaskStackSize = configMINIMAL_STACK_SIZE;
  /* place for user code */
}
/* USER CODE END GET_IDLE_TASK_MEMORY */
